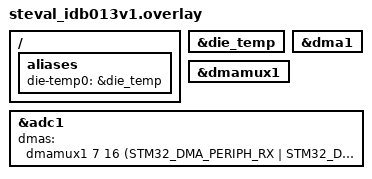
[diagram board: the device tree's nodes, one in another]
/ {
	aliases {
		die-temp0 = &die_temp;
	};
};

&die_temp {
	status = "okay";
};

&dma1 {
	status = "okay";
};

&dmamux1 {
	status = "okay";
};

&adc1 {
	dmas = <&dmamux1 7 16 (STM32_DMA_PERIPH_RX | STM32_DMA_MEM_16BITS |
		STM32_DMA_PERIPH_16BITS)>;
	dma-names = "dmamux";

	status = "okay";
};
